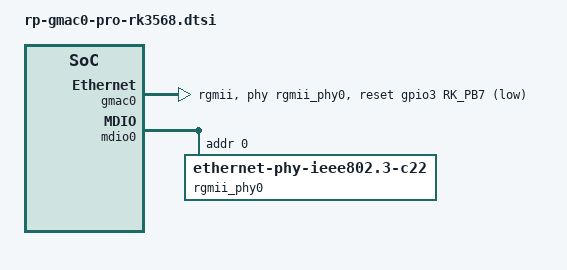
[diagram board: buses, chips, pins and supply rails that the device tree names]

&gmac0 {
	phy-mode = "rgmii";
	clock_in_out = "input";

//	snps,reset-gpio = <&gpio2 RK_PD3 GPIO_ACTIVE_LOW>;
	snps,reset-gpio = <&gpio3 RK_PB7 GPIO_ACTIVE_LOW>;
	snps,reset-active-low;
	/* Reset time is 20ms, 100ms for rtl8211f */
	snps,reset-delays-us = <0 20000 100000>;

	assigned-clocks = <&cru SCLK_GMAC0_RX_TX>, <&cru SCLK_GMAC0>, <&cru CLK_MAC0_OUT>;
	assigned-clock-parents = <&cru SCLK_GMAC0_RGMII_SPEED>, <&gmac0_clkin>, <&cru CLK_MAC0_2TOP>;
	assigned-clock-rates = <0>, <125000000>, <25000000>;

	pinctrl-names = "default";
	pinctrl-0 = <&gmac0_miim
		     &gmac0_tx_bus2
		     &gmac0_rx_bus2
		     &gmac0_rgmii_clk
		     &gmac0_rgmii_bus
			&eth0_pins
			&gmac0_clkinout>;

	tx_delay = <0x2d>;
	rx_delay = <0x2c>;
	phy-handle = <&rgmii_phy0>;
	status = "okay";
};


&mdio0 {
	rgmii_phy0: phy@0 {
		compatible = "ethernet-phy-ieee802.3-c22";
		reg = <0x0>;
		clocks = <&cru CLK_MAC0_OUT>;
	};
};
